VERSION "1.0"

NS_ :

BS_:

BU_: Engine Brake Gateway

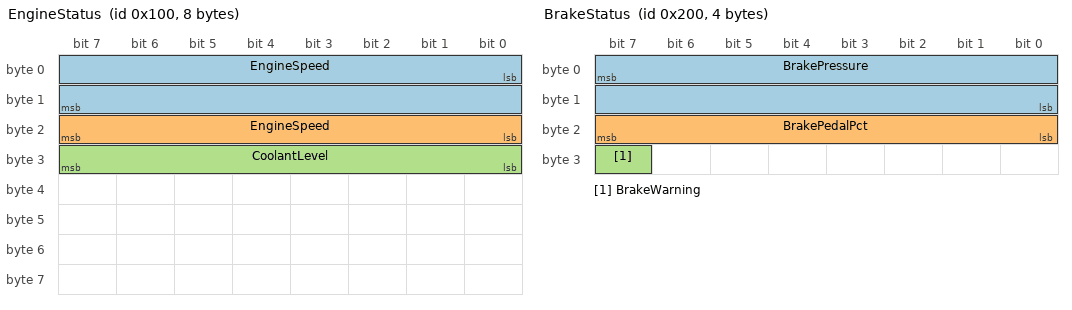
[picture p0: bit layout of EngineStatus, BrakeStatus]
BO_ 256 EngineStatus: 8 Engine
 SG_ EngineSpeed : 0|16@1+ (0.25,0) [0|8000] "rpm" Gateway,Brake
 SG_ EngineSpeed : 16|8@1+ (1,-40) [-40|215] "degC" Gateway
 SG_ CoolantLevel : 24|8@1+ (1,0) [0|255] "" Vector__XXX

BO_ 512 BrakeStatus: 4 Brake
 SG_ BrakePressure : 7|16@0+ (0.1,0) [0|6553.5] "bar" Gateway
 SG_ BrakePedalPct : 23|8@0- (0.5,0) [-64|63.5] "%" Gateway
 SG_ BrakeWarning : 31|1@0+ (1,0) [0|1] "" Gateway
